# CY8C3246PVI_147 register map
File version: 0.1
CY8C32
Registers are 8-bit, read-write, no defined reset value unless marked. A register's access mark holds for its fields unless they carry their own. Offsets are from the block's base; lines under a group give offsets from that group; [hi:lo] are bit positions; {n}, {i} and the like mark numbered series; 'fields as' and 'values as' point back to an identical list; <NAME> marks a mode.

## Memory map
0x00000000 Morse_Counter
0x00000000 USBFS
0x00006469 Status
0x00006479 Control

## Status
Base 0x00006469
0x00 Status_STATUS_REG
0x20 Status_MASK_REG
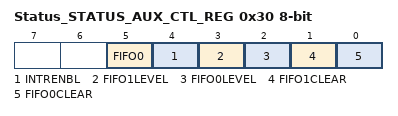
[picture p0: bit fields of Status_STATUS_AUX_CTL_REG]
0x30 Status_STATUS_AUX_CTL_REG
  [5] FIFO0 — FIFO0 clear
    1=ENABLED (Enable counter); 0=DISABLED (Disable counter)
  [4] INTRENBL — Enables or disables the Interrupt
    1=ENABLED (Interrupt enabled); 0=DISABLED (Interrupt disabled)
  [3] FIFO1LEVEL — FIFO level
    1=ENABLED (FIFO LVL: input mode: FIFO at least 1/2 empty; output mode: FIFO at least 1/2 full); 0=DISABLED (FIFO LVL: input mode: FIFO not full; output mode: FIFO not empty)
  [2] FIFO0LEVEL — FIFO level
    values as FIFO1LEVEL
  [1] FIFO1CLEAR — FIFO clear
    1=ENABLED (Clear FIFO state); 0=DISABLED (Normal FIFO operation)
  [0] FIFO0CLEAR — FIFO clear
    values as FIFO1CLEAR

## Morse_Counter
Base 0x00000000
0x43A3 Morse_Counter_GLOBAL_ENABLE — PM.ACT.CFG
  [3:0] en_timer — Enable timer/counters.
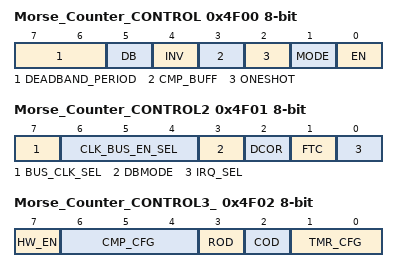
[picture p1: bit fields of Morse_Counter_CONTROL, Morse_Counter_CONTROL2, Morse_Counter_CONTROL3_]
0x4F00 Morse_Counter_CONTROL — TMRx.CFG0
  [7:6] DEADBAND_PERIOD
  [5] DB — Deadband mode--Deadband phases phi1 and phi2 are outputted on CMP and TC output pins respectively.
    0=Timer (CMP and TC are output.); 1=Deadband (PHI1 (instead of CMP) and PHI2 (instead of TC) are output.)
  [4] INV — Invert sense of TIMEREN signal
  [3] CMP_BUFF — Buffer compare register. Compare register updates only on timer terminal count.
  [2] ONESHOT — Timer stops upon reaching stop condition defined by TMR_CFG bits. Can be restarted by asserting TIMER RESET or disabling and re-enabling block.
  [1] MODE — Mode. (0 = Timer; 1 = Comparator)
    0=Timer mode. CNT/CMP register holds timer count value.; 1=Comparator mode. CNT/CMP register holds comparator threshold value.
  [0] EN — Enables timer/comparator.
0x4F01 Morse_Counter_CONTROL2 — TMRx.CFG1
  [7] BUS_CLK_SEL — Bus Clock selection.
  [6:4] CLK_BUS_EN_SEL — Digital Global Clock selection.
  [3] DBMODE — Deadband mode (asynchronous/synchronous). CMP output pin is also affected when not in deadband mode (CFG0.DEADBAND).
  [2] DCOR — Disable Clear on Read (DCOR) of Status Register SR0.
  [1] FTC — First Terminal Count (FTC). Setting this bit forces a single pulse on the TC pin when first enabled.
    0=Disable_FTC (Disable the single cycle pulse, which signifies the timer is starting.); 1=Enable_FTC (Enable the single cycle pulse, which signifies the timer is starting.)
  [0] IRQ_SEL — Irq selection. (0 = raw interrupts; 1 = status register interrupts)
0x4F02 Morse_Counter_CONTROL3_ — TMRx.CFG2
  [7] HW_EN — When set Timer Enable controls counting.
  [6:4] CMP_CFG — Comparator configurations
    0=Equal (Compare Equal); 1=Less_than (Compare Less Than); 2=Less_than_or_equal (Compare Less Than or Equal .); 3=Greater (Compare Greater Than .); 4=Greater_than_or_equal (Compare Greater Than or Equal)
  [3] ROD — Reset On Disable (ROD). Resets internal state of output logic
  [2] COD — Clear On Disable (COD). Clears or gates outputs to zero.
  [1:0] TMR_CFG — Timer configuration (MODE = 0): 000 = Continuous; 001 = Pulsewidth; 010 = Period; 011 = Stop on IRQ
    0=Continuous (Timer runs while EN bit of CFG0 register is set to '1'.); 1=Pulsewidth (Timer runs from positive to negative edge of TIMEREN.); 2=Period (Timer runs from positive to positive edge of TIMEREN.); 3=Irq (Timer runs until IRQ.)
0x4F04 Morse_Counter_PERIOD — TMRx.PER0 - Assigned Period
0x4F06 Morse_Counter_COUNTER — TMRx.CNT_CMP0 - Current Down Counter Value

## Control
Base 0x00006479
0x00 Control_CONTROL_REG

## USBFS
Base 0x00000000
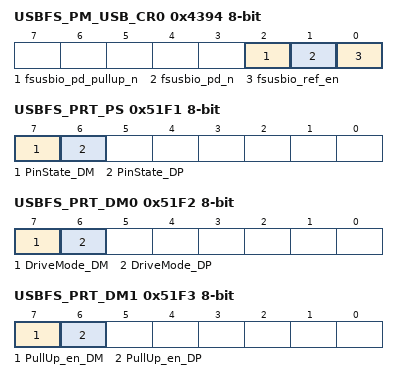
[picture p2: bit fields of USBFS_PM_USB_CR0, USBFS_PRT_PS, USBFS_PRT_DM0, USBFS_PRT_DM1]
0x4394 USBFS_PM_USB_CR0 — USB Power Mode Control Register 0
  [2] fsusbio_pd_pullup_n, [1] fsusbio_pd_n, [0] fsusbio_ref_en
0x43A5 USBFS_PM_ACT_CFG — Active Power Mode Configuration Register
0x43B5 USBFS_PM_STBY_CFG — Standby Power Mode Configuration Register
0x51F1 USBFS_PRT_PS — Port Pin State Register
  [7] PinState_DM ro, [6] PinState_DP ro
0x51F2 USBFS_PRT_DM0 — Port Drive Mode Register
  [7] DriveMode_DM, [6] DriveMode_DP
0x51F3 USBFS_PRT_DM1 — Port Drive Mode Register
  [7] PullUp_en_DM, [6] PullUp_en_DP
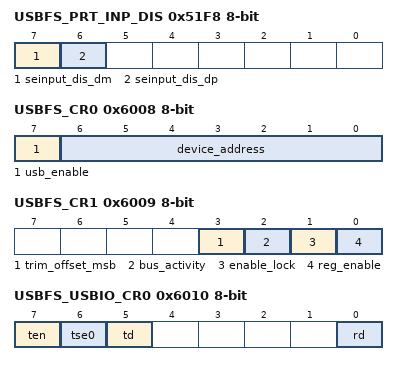
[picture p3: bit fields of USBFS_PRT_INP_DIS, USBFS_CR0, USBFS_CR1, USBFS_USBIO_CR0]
0x51F8 USBFS_PRT_INP_DIS — Input buffer disable override
  [7] seinput_dis_dm, [6] seinput_dis_dp
0x6000 USBFS_EP0_DR0 — bmRequestType
0x6001 USBFS_EP0_DR1 — bRequest
0x6002 USBFS_EP0_DR2 — wValueLo
0x6003 USBFS_EP0_DR3 — wValueHi
0x6004 USBFS_EP0_DR4 — wIndexLo
0x6005 USBFS_EP0_DR5 — wIndexHi
0x6006 USBFS_EP0_DR6 — lengthLo
0x6007 USBFS_EP0_DR7 — lengthHi
0x6008 USBFS_CR0 — USB Control Register 0
  [7] usb_enable, [6:0] device_address ro
0x6009 USBFS_CR1 — USB Control Register 1
  [3] trim_offset_msb, [2] bus_activity, [1] enable_lock, [0] reg_enable
{0x5FFE+0x10*i} USBFS_SIE_EP{i}_CR0 (i=1..8) — The Endpoint{i} Control Register
0x6010 USBFS_USBIO_CR0 — USBIO Control Register 0
  [7] ten, [6] tse0, [5] td, [0] rd ro
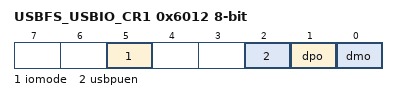
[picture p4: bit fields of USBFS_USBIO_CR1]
0x6012 USBFS_USBIO_CR1 — USBIO Control Register 1
  [5] iomode, [2] usbpuen, [1] dpo ro, [0] dmo ro
0x608C USBFS_BUF_SIZE — Dedicated Endpoint Buffer Size Register
0x608E USBFS_EP_ACTIVE — Endpoint Active Indication Register
0x608F USBFS_EP_TYPE — Endpoint Type (IN/OUT) Indication
0x609D USBFS_USB_CLK_EN — USB Block Clock Enable Register
